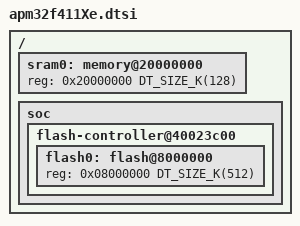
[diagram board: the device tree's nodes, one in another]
/*
 * Copyright (c) 2023, Quincy.W <wangqyfm@foxmail.com>
 * SPDX-License-Identifier: Apache-2.0
 */

#include <mem.h>
#include <geehy/f4/apm32f411.dtsi>

/ {
	sram0: memory@20000000 {
		reg = <0x20000000 DT_SIZE_K(128)>;
	};

	soc {
		flash-controller@40023c00 {
			flash0: flash@8000000 {
				reg = <0x08000000 DT_SIZE_K(512)>;
			};
		};
	};
};
